# STM32F413CGU3 register map
File version: 1.0
Registers are 32-bit, access not given, reset 0x0 unless marked. A register's access mark holds for its fields unless they carry their own. Offsets are from the block's base; [hi:lo] are bit positions; {n}, {i} and the like mark numbered series; 'fields as' and 'values as' point back to an identical list.

## PWR
Base 0x40007000
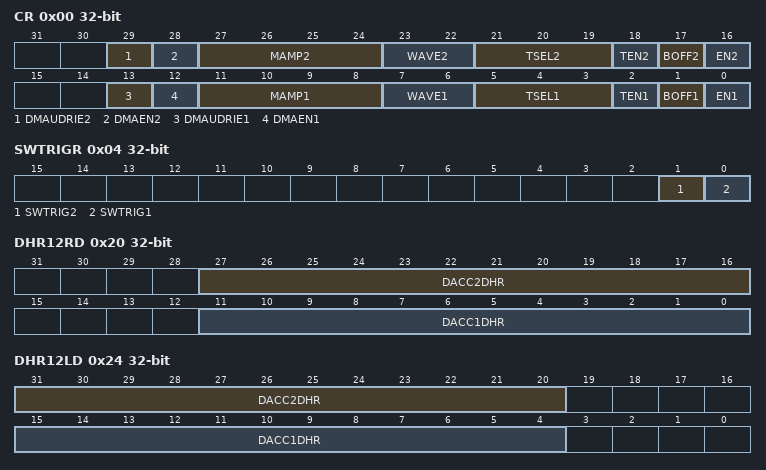
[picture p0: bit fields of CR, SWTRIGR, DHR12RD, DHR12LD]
0x00 CR
0x04 CSR

## DAC
Base 0x40007400
0x00 CR
  [29] DMAUDRIE2, [28] DMAEN2, [27:24] MAMP2, [23:22] WAVE2, [21:19] TSEL2, [18] TEN2, [17] BOFF2, [16] EN2, [13] DMAUDRIE1, [12] DMAEN1, [11:8] MAMP1, [7:6] WAVE1, [5:3] TSEL1, [2] TEN1, [1] BOFF1, [0] EN1
0x04 SWTRIGR
  [1] SWTRIG2, [0] SWTRIG1
0x08 DHR12R1
  [11:0] DACC1DHR
0x0C DHR12L1
  [15:4] DACC1DHR
0x10 DHR8R1
  [7:0] DACC1DHR
0x14 DHR12R2
  [11:0] DACC2DHR
0x18 DHR12L2
  [15:4] DACC2DHR
0x1C DHR8R2
  [7:0] DACC2DHR
0x20 DHR12RD
  [27:16] DACC2DHR, [11:0] DACC1DHR
0x24 DHR12LD
  [31:20] DACC2DHR, [15:4] DACC1DHR
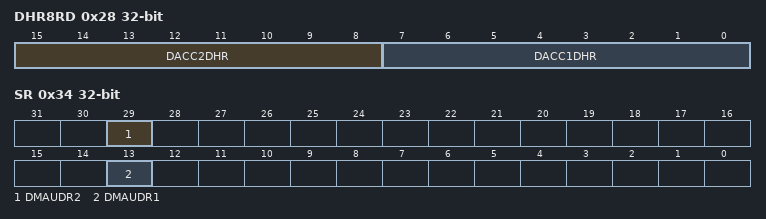
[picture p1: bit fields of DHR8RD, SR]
0x28 DHR8RD
  [15:8] DACC2DHR, [7:0] DACC1DHR
0x2C DOR1
  [11:0] DACC1DOR
0x30 DOR2
  [11:0] DACC2DOR
0x34 SR
  [29] DMAUDR2, [13] DMAUDR1

## ADC1
Base 0x40012000
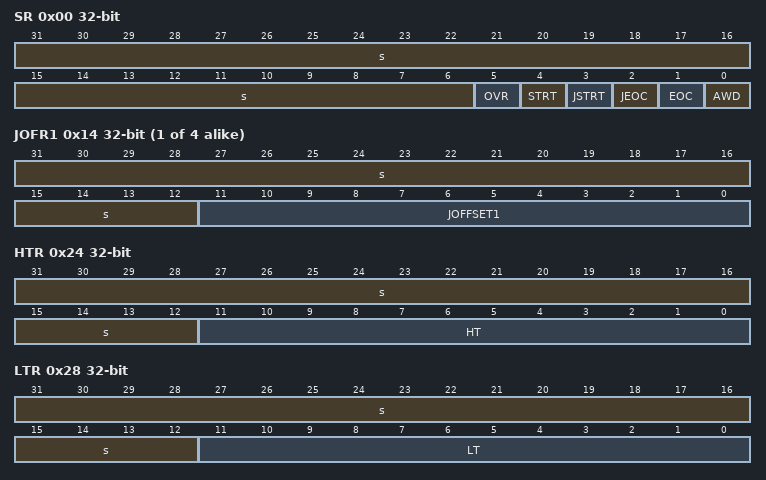
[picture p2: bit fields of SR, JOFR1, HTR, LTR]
0x00 SR
  [31:6] s, [5] OVR, [4] STRT, [3] JSTRT, [2] JEOC, [1] EOC, [0] AWD
0x04 CR1
  [26] OVRIE, [25:24] RES, [23] AWDEN, [22] JAWDEN, [31:16] s, [15:13] DISCNUM, [12] JDISCEN, [11] DISCEN, [10] JAUTO, [9] AWDSGL, [8] SCAN, [7] JEOCIE, [6] AWDIE, [5] EOCIE, [4:0] AWDCH
0x08 CR2
  [30] SWSTART, [29:28] EXTEN, [27:24] EXTSEL, [22] JSWSTART, [21:20] JEXTEN, [19:16] JEXTSEL, [11] ALIGN, [10] EOCS, [9] DDS, [8] DMA, [31:2] s, [1] CONT, [0] ADON
0x0C SMPR1
  [31:0] SMP
0x10 SMPR2
  [31:0] SMP
{0x10+4i} JOFR{i} (i=1..4)
  [31:12] s, [11:0] JOFFSET{i}
0x24 HTR
  [31:12] s, [11:0] HT
0x28 LTR
  [31:12] s, [11:0] LT
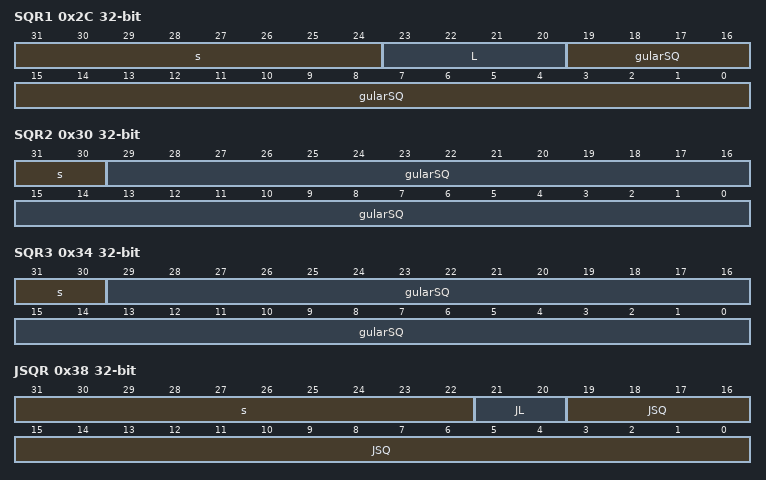
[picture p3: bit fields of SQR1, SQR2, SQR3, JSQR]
0x2C SQR1
  [31:24] s, [23:20] L, [19:0] gularSQ
0x30 SQR2
  [31:30] s, [29:0] gularSQ
0x34 SQR3
  [31:30] s, [29:0] gularSQ
0x38 JSQR
  [31:22] s, [21:20] JL, [19:0] JSQ
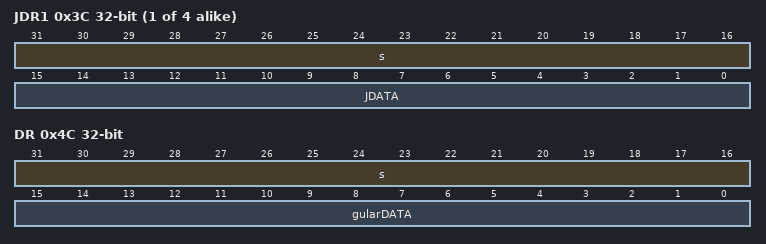
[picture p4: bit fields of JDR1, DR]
{0x38+4i} JDR{i} (i=1..4)
  [31:16] s, [15:0] JDATA
0x4C DR
  [31:16] s, [15:0] gularDATA

## SDIO
Base 0x40012C00
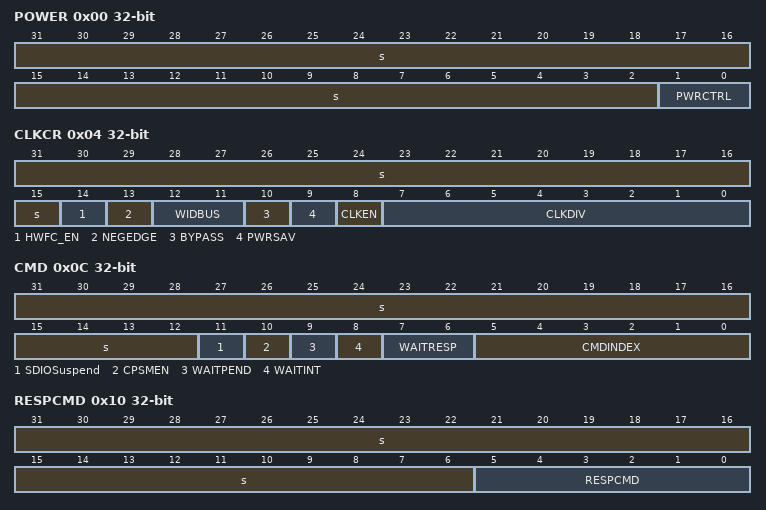
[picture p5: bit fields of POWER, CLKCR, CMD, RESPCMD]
0x00 POWER
  [31:2] s, [1:0] PWRCTRL
0x04 CLKCR
  [31:15] s, [14] HWFC_EN, [13] NEGEDGE, [12:11] WIDBUS, [10] BYPASS, [9] PWRSAV, [8] CLKEN, [7:0] CLKDIV
0x08 ARG
  [31:0] CMDARG
0x0C CMD
  [31:12] s, [11] SDIOSuspend, [10] CPSMEN, [9] WAITPEND, [8] WAITINT, [7:6] WAITRESP, [5:0] CMDINDEX
0x10 RESPCMD
  [31:6] s, [5:0] RESPCMD
{0x10+4i} RESP{i} (i=1..4)
  [31:0] CARDSTATUS{i}
0x24 DTIMER
  [31:0] DATATIME
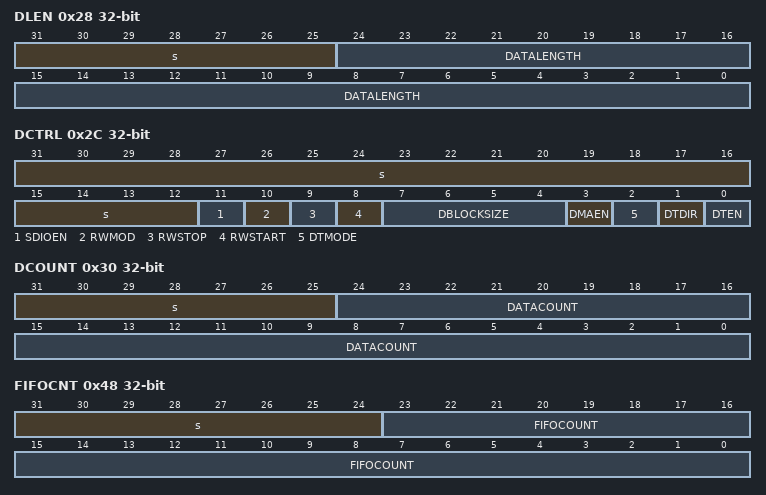
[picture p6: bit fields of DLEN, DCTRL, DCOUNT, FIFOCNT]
0x28 DLEN
  [31:25] s, [24:0] DATALENGTH
0x2C DCTRL
  [31:12] s, [11] SDIOEN, [10] RWMOD, [9] RWSTOP, [8] RWSTART, [7:4] DBLOCKSIZE, [3] DMAEN, [2] DTMODE, [1] DTDIR, [0] DTEN
0x30 DCOUNT
  [31:25] s, [24:0] DATACOUNT
0x34 STA
  [22] SDIOIT, [21] RXDAVL, [20] TXDAVL, [19] RXFIFOE, [18] TXFIFOE, [17] RXFIFOF, [16] TXFIFOF, [15] RXFIFOHF, [14] TXFIFOHE, [13] RXACT, [12] TXACT, [11] CMDACT, [10] DBCKEND, [31:9] s, [8] DATAEND, [7] CMDSENT, [6] CMDREND, [5] RXOVERR, [4] TXUNDERR, [3] DTIMEOUT, [2] CTIMEOUT, [1] DCRCFAIL, [0] CCRCFAIL
0x38 ICR
  [22] SDIOITC, [10] DBCKENDC, [31:9] s, [8] DATAENDC, [7] CMDSENTC, [6] CMDRENDC, [5] RXOVERRC, [4] TXUNDERRC, [3] DTIMEOUTC, [2] CTIMEOUTC, [1] DCRCFAILC, [0] CCRCFAILC
0x3C MASK
  [22] SDIOITIE, [21] RXDAVLIE, [20] TXDAVLIE, [19] RXFIFOEIE, [18] TXFIFOEIE, [17] RXFIFOFIE, [16] TXFIFOFIE, [15] RXFIFOHFIE, [14] TXFIFOHEIE, [13] RXACTIE, [12] TXACTIE, [11] CMDACTIE, [10] DBCKENDIE, [31:9] s, [8] DATAENDIE, [7] CMDSENTIE, [6] CMDRENDIE, [5] RXOVERRIE, [4] TXUNDERRIE, [3] DTIMEOUTIE, [2] CTIMEOUTIE, [1] DCRCFAILIE, [0] CCRCFAILIE
0x48 FIFOCNT
  [31:24] s, [23:0] FIFOCOUNT
0x80 FIFO
  [31:0] FIF0Data

## SYSCFG
Base 0x40013800
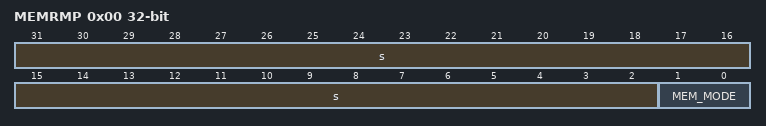
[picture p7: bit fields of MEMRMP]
0x00 MEMRMP
  [31:2] s, [1:0] MEM_MODE
0x04 PMC
{0x4+4i} EXTICR{i} (i=1..4)
0x1C CFGR2
0x20 CMPCR
0x2C CFGR
  [0] 0I2CFMP1_SCL
0x30 MCHDLYCR

## EXTI
Base 0x40013C00
0x00 IMR
0x04 EMR
0x08 RTSR
0x0C FTSR
0x10 SWIER
0x14 PR

## SAI1
Base 0x40015800
0x04 CR1A
  [23:20] MCKDIV, [19] NODIV, [17] DMAEN, [16] SAIxEN, [13] OutDri, [12] MONO, [11:10] SYNCEN, [9] CKSTR, [8] LSBFIRST, [7:5] DS, [18:4] s, [3:2] PRTCFG, [1:0] MODE
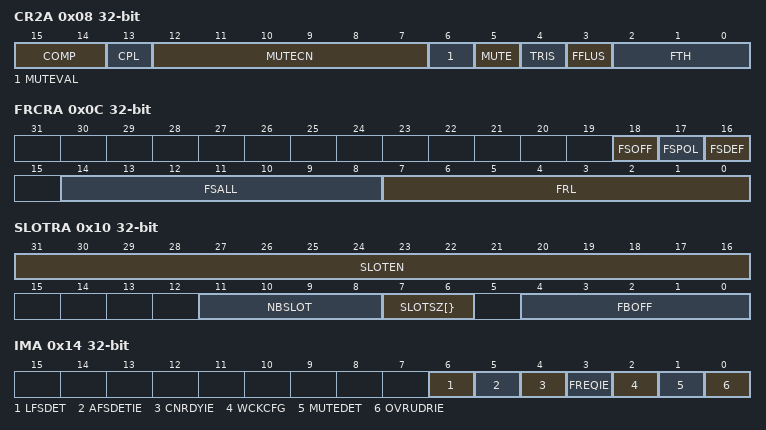
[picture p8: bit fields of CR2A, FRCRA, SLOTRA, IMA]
0x08 CR2A
  [15:14] COMP, [13] CPL, [12:7] MUTECN, [6] MUTEVAL, [5] MUTE, [4] TRIS, [3] FFLUS, [2:0] FTH
0x0C FRCRA
  [18] FSOFF, [17] FSPOL, [16] FSDEF, [14:8] FSALL, [7:0] FRL
0x10 SLOTRA
  [31:16] SLOTEN, [11:8] NBSLOT, [7:6] SLOTSZ[}, [4:0] FBOFF
0x14 IMA
  [6] LFSDET, [5] AFSDETIE, [4] CNRDYIE, [3] FREQIE, [2] WCKCFG, [1] MUTEDET, [0] OVRUDRIE
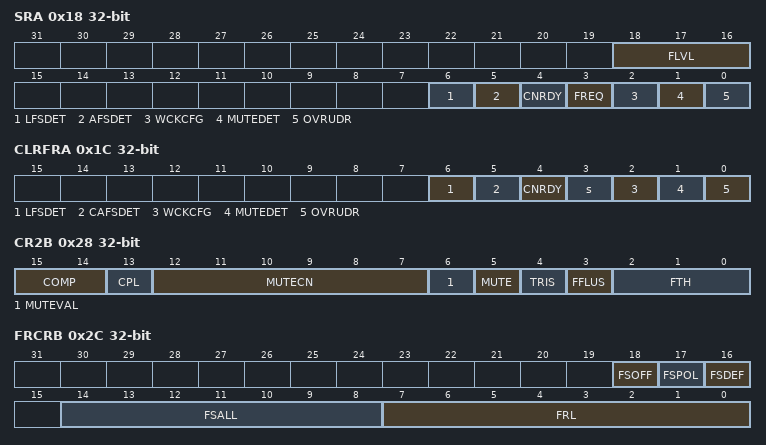
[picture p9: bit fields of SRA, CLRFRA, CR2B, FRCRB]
0x18 SRA
  [18:16] FLVL, [6] LFSDET, [5] AFSDET, [4] CNRDY, [3] FREQ, [2] WCKCFG, [1] MUTEDET, [0] OVRUDR
0x1C CLRFRA
  [6] LFSDET, [5] CAFSDET, [4] CNRDY, [3] s, [2] WCKCFG, [1] MUTEDET, [0] OVRUDR
0x20 DRA
  [31:0] DATA
0x24 CR1B
  fields as CR1A
0x28 CR2B
  fields as CR2A
0x2C FRCRB
  [18] FSOFF, [17] FSPOL, [16] FSDEF, [14:8] FSALL, [7:0] FRL
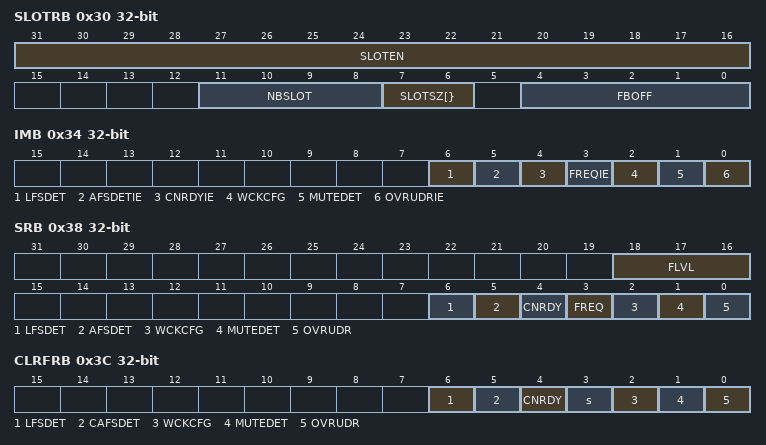
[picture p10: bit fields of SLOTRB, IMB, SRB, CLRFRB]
0x30 SLOTRB
  [31:16] SLOTEN, [11:8] NBSLOT, [7:6] SLOTSZ[}, [4:0] FBOFF
0x34 IMB
  fields as IMA
0x38 SRB
  fields as SRA
0x3C CLRFRB
  fields as CLRFRA
0x40 DRB
  [31:0] DATA
